# STM32MP13xx register map
File version: 1.5
CPU: CA7 r0p0, little endian, MPU, FPU, 4 interrupt priority bits
Registers are 32-bit, read-write, reset 0x0 unless marked. A register's access mark holds for its fields unless they carry their own. Offsets are from the block's base; [hi:lo] are bit positions.

## RNG
Base 0x54004000
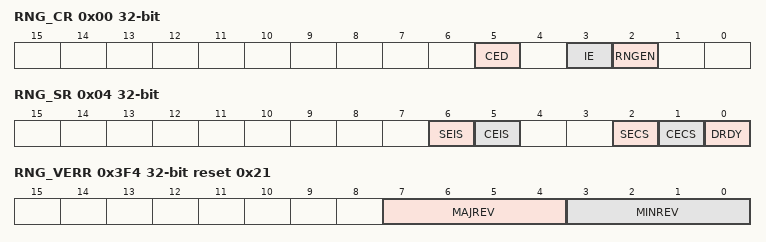
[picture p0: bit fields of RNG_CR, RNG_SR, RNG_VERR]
0x00 RNG_CR — RNG control register
  [5] CED — Clock error detection The clock error detection cannot be enabled nor disabled on-the-fly when the RNG is enabled, i.e. to enable or disable CED the RNG must be disabled.
    0=Clock error detection is enable; 1=Clock error detection is disable
  [3] IE — Interrupt Enable
    0=RNG Interrupt is disabled; 1=RNG Interrupt is enabled. An interrupt is pending as soon as DRDY='1', SEIS='1' or CEIS=1 in the RNG_SR register.
  [2] RNGEN — True random number generator enable
    0=True random number generator is disabled. Analog noise sources are powered off and logic clocked by the RNG clock is gated.; 1=True random number generator is enabled
0x04 RNG_SR access per field — RNG status register
  [6] SEIS rw — Seed error interrupt status This bit is set at the same time as SECS. It is cleared by writing 0. Writing 1 has no effect. An interrupt is pending if IE = 1 in the RNG_CR register.
    0=No faulty sequence detected; 1=At least one faulty sequence has been detected. See SECS bit description for details.
  [5] CEIS rw — Clock error interrupt status This bit is set at the same time as CECS. It is cleared by writing 0. Writing 1 has no effect. An interrupt is pending if IE = 1 in the RNG_CR register.
    0=The RNG clock is correct (fRNGCLK> fHCLK/32); 1=The RNG has been detected too slow (fRNGCLK< fHCLK/32)
  [2] SECS ro — Seed error current status One of the noise source has provided more than 64 consecutive bits at a constant value (â0â or â1â), or more than 32 consecutive occurrence of two bit patterns (â01â or â10â) Both noise sources have delivered more than 32 consecutive bits at a constant value (â0â or â1â), or more than 16 consecutive occurrence of two bit patterns (â01â or â10â)
    0=No faulty sequence has currently been detected. If the SEIS bit is set, this means that a faulty sequence was detected and the situation has been recovered.; 1=At least one of the following faulty sequence has been detected:
  [1] CECS ro — Clock error current status Note: CECS bit is valid only if the CED bit in the RNG_CR register is set to 0.
    0=The RNG clock is correct (fRNGCLK> fHCLK/32). If the CEIS bit is set, this means that a slow clock was detected and the situation has been recovered.; 1=The RNG clock is too slow (fRNGCLK< fHCLK/32)
  [0] DRDY ro — Data Ready Once the output buffer becomes empty (after reading the RNG_DR register), this bit returns to 0 until a new random value is generated. Note: The DRDY bit can rise when the peripheral is disabled (RNGEN=0 in the RNG_CR register). If IE=1 in the RNG_CR register, an interrupt is generated when DRDY=1.
    0=The RNG_DR register is not yet valid, no random data is available; 1=The RNG_DR register contains valid random data
0x08 RNG_DR ro — RNG data register
  [31:0] RNDATA — Random data 32-bit random data which are valid when DRDY=1. When DRDY=0 RNDATA value is zero. It is recommended to always verify that RNG_DR is different from zero. Because when it is the case a seed error occurred between RNG_SR polling and RND_DR output reading (rare event).
0x3F4 RNG_VERR ro reset 0x21 — RNG version register
  [7:4] MAJREV — Major revision This bitfield returns the RNG peripheral major version.
  [3:0] MINREV — Minor revision This bitfield returns the RNG peripheral minor version.
0x3F8 RNG_IPIDR ro reset 0x170041 — RNG identification register
  [31:0] ID — Identification code of the peripheral This bitfield returns the identification code of the RNG peripheral.
0x3FC RNG_SIDR ro reset 0xA3C5DD01 — RNG size ID register
  [31:0] SID — Size identification code This bitfield returns the size identification code of the RNG peripheral as defined below: Bits[31:8] = 0xA3C5DD (fixed code) Bits[7:0] = 0x01 (1 Kbyte address decoding)
